VERSION ""

NS_ :

BS_:

BU_: Inverter ACAN Dashboard ECU
VAL_TABLE_ Discharge 1 "Discharge Enabled" 0 "Discharge Disabled" ;
VAL_TABLE_ Enabled 1 "Enabled" 0 "Disabled" ;
VAL_TABLE_ Direction 1 "Forward" 0 "Reverse" ;
VAL_TABLE_ Fault_POST 1073741824 "Brake Shorted" 536870912 "Reserved" 268435456 "Reserved" 134217728 "Reserved" 67108864 "EEPROM Update Required" 33554432 "EEPROM Data Out of Range" 16777216 "EEPROM Checksum Invalid" 8388608 "Pre-Charge Voltage Failure" 4194304 "Pre-Charge Timeout" 2097152 "DC Bus Voltage Low" 1048576 "DC Bus Voltage High" 524288 "1.5V Sense Voltage High" 262144 "1.5V Sense Voltage Low" 131072 "2.5V Sense Voltage High" 65536 "2.5V Sense Voltage Low" 32768 "12V Sense Voltage High" 16384 "12V Sense Voltage Low" 8192 "5V Sense Voltage High" 4096 "5V Sense Voltage Low" 2048 "Gate Drive PCB Temperature High" 1024 "Gate Drive PCB Temperature Low" 512 "Control PCB Temperature High" 256 "Control PCB Temperature Low" 128 "Module Temperature High" 64 "Module Temperature Low" 32 "Current Sensor High" 16 "Current Sensor Low" 8 "Accelerator Open" 4 "Accelerator Shorted" 2 "HW Over-current Fault" 1 "Hardware Gate/Desaturation Fault" 0 "No Faults" -2147483648 "Brake Open" ;
VAL_TABLE_ Button 1 "High" 0 "Low" ;

BO_ 3221225472 VECTOR__INDEPENDENT_SIG_MSG: 0 Vector__XXX
 SG_ Error_POST_Fault : 0|32@1+ (1,0) [0|4294967295] "Enumerable" Vector__XXX
 SG_ APPS_2_Scaled : 0|16@1+ (1,0) [0|65535] "ADC" Vector__XXX

BO_ 1797 TMP__ECU_Message_Status: 2 Vector__XXX
 SG_ TMP_message_received : 0|1@1+ (1,0) [0|1] "Bool" Vector__XXX
 SG_ TMP_message_not_received_count : 8|8@1+ (1,0) [0|1] "Count" Vector__XXX

BO_ 1795 TMP_SEND_REQUEST: 4 Vector__XXX
 SG_ TMP_Torque : 16|16@1+ (0.1,0) [0|65535] "Nm" Vector__XXX
 SG_ TMP_APPS_1 : 0|16@1+ (1,0) [0|65535] "ADC" Vector__XXX

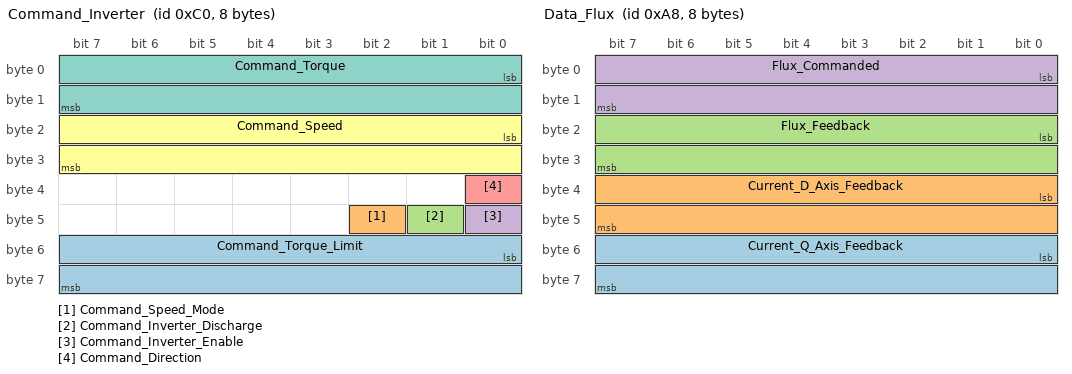
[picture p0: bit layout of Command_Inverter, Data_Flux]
BO_ 192 Command_Inverter: 8 ECU
 SG_ Command_Torque_Limit : 48|16@1- (0.1,0) [-3276.8|3276.7] "Newton Meters"  Inverter
 SG_ Command_Speed_Mode : 42|1@1+ (1,0) [0|1] "Boolean"  Inverter
 SG_ Command_Inverter_Discharge : 41|1@1+ (1,0) [0|1] "Boolean"  Inverter
 SG_ Command_Inverter_Enable : 40|1@1+ (1,0) [0|1] "Boolean"  Inverter
 SG_ Command_Direction : 32|1@1+ (1,0) [0|1] "Boolean"  Inverter
 SG_ Command_Speed : 16|16@1- (1,0) [-32768|32767] "RPM"  Inverter
 SG_ Command_Torque : 0|16@1- (0.1,0) [-3276.8|3276.7] "Newton Meters"  Inverter

BO_ 168 Data_Flux: 8 Inverter
 SG_ Current_Q_Axis_Feedback : 48|16@1- (0.1,0) [-3276.8|3276.7] "Amps" Vector__XXX
 SG_ Current_D_Axis_Feedback : 32|16@1- (0.1,0) [-3276.8|3276.7] "Amps" Vector__XXX
 SG_ Flux_Feedback : 16|16@1- (0.001,0) [-32.768|32.767] "Webers" Vector__XXX
 SG_ Flux_Commanded : 0|16@1- (0.001,0) [-32.768|32.767] "Webers" Vector__XXX

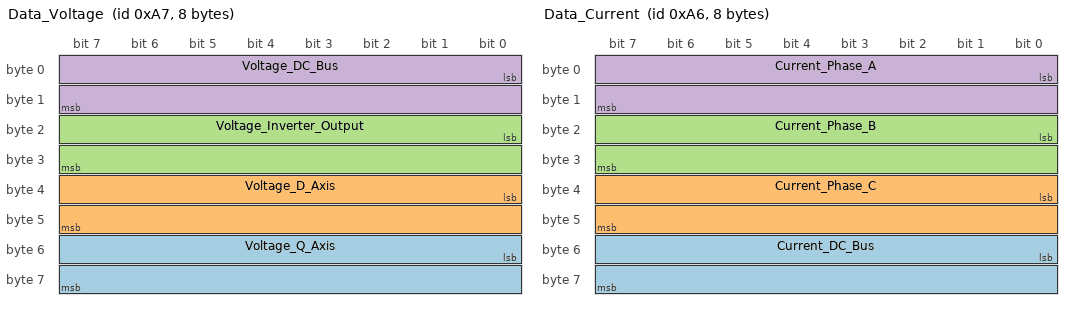
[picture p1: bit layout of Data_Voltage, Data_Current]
BO_ 167 Data_Voltage: 8 Inverter
 SG_ Voltage_Q_Axis : 48|16@1- (0.1,0) [-3276.8|3276.7] "Volts" Vector__XXX
 SG_ Voltage_D_Axis : 32|16@1- (0.1,0) [-3276.8|3276.7] "Volts" Vector__XXX
 SG_ Voltage_Inverter_Output : 16|16@1- (0.1,0) [-3276.8|3276.7] "Volts" Vector__XXX
 SG_ Voltage_DC_Bus : 0|16@1- (0.1,0) [-3276.8|3276.7] "Volts" Vector__XXX

BO_ 166 Data_Current: 8 Inverter
 SG_ Current_DC_Bus : 48|16@1- (0.1,0) [-3276.8|3276.7] "Amps" Vector__XXX
 SG_ Current_Phase_C : 32|16@1- (0.1,0) [-3276.8|3276.7] "Amps" Vector__XXX
 SG_ Current_Phase_B : 16|16@1- (0.1,0) [-3276.8|3276.7] "Amps" Vector__XXX
 SG_ Current_Phase_A : 0|16@1- (0.1,0) [-3276.8|3276.7] "Amps" Vector__XXX

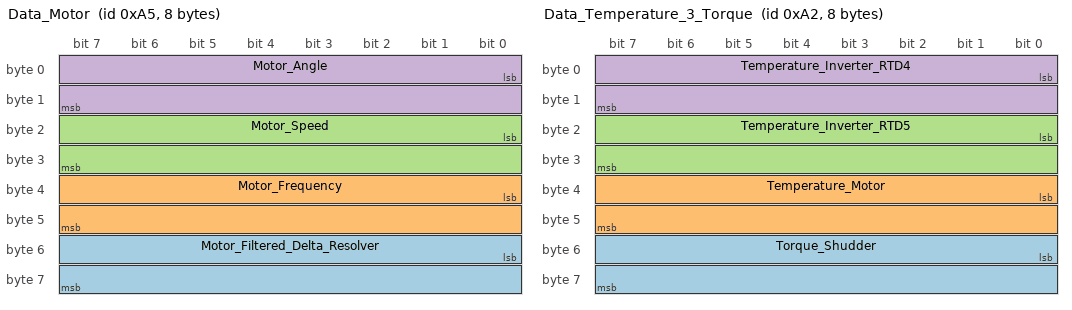
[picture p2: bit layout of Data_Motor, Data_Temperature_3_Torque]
BO_ 165 Data_Motor: 8 Inverter
 SG_ Motor_Filtered_Delta_Resolver : 48|16@1- (0.1,0) [-359.9|359.9] "Degrees" Vector__XXX
 SG_ Motor_Frequency : 32|16@1- (0.1,0) [-3276.8|3276.7] "Hz" Vector__XXX
 SG_ Motor_Speed : 16|16@1- (1,0) [-32768|32767] "RPM" Vector__XXX
 SG_ Motor_Angle : 0|16@1- (0.1,0) [-359.9|359.9] "Degrees" Vector__XXX

BO_ 162 Data_Temperature_3_Torque: 8 Inverter
 SG_ Torque_Shudder : 48|16@1- (0.1,0) [-3276.8|3276.7] "Newton Meters" Vector__XXX
 SG_ Temperature_Motor : 32|16@1- (0.1,0) [-3276.8|3276.7] "Celcius" Vector__XXX
 SG_ Temperature_Inverter_RTD5 : 16|16@1- (0.1,0) [-3276.8|3276.7] "Celcius" Vector__XXX
 SG_ Temperature_Inverter_RTD4 : 0|16@1- (0.1,0) [-3276.8|3276.7] "Celcius" Vector__XXX

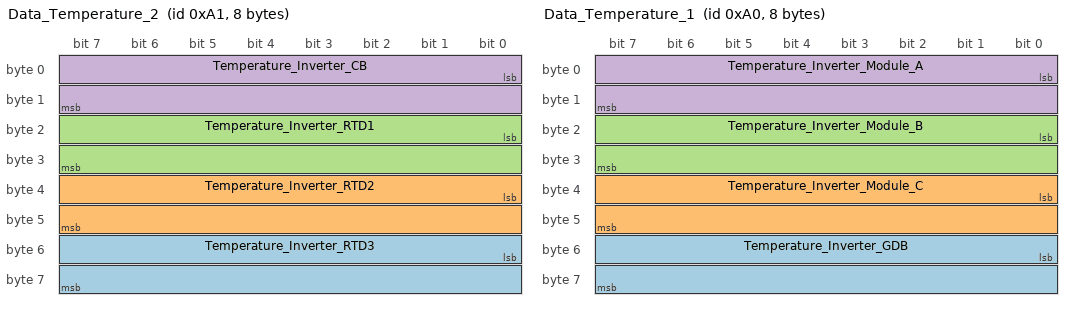
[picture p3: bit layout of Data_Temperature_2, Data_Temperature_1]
BO_ 161 Data_Temperature_2: 8 Inverter
 SG_ Temperature_Inverter_RTD3 : 48|16@1- (0.1,0) [-3276.8|3276.7] "Celcius" Vector__XXX
 SG_ Temperature_Inverter_RTD2 : 32|16@1- (0.1,0) [-3276.8|3276.7] "Celcius" Vector__XXX
 SG_ Temperature_Inverter_RTD1 : 16|16@1- (0.1,0) [-3276.8|3276.7] "Celcius" Vector__XXX
 SG_ Temperature_Inverter_CB : 0|16@1- (0.1,0) [-3276.8|3276.7] "Celcius" Vector__XXX

BO_ 160 Data_Temperature_1: 8 Inverter
 SG_ Temperature_Inverter_GDB : 48|16@1- (0.1,0) [-3276.8|3276.7] "Celcius" Vector__XXX
 SG_ Temperature_Inverter_Module_C : 32|16@1- (0.1,0) [-3276.8|3276.7] "Celcius" Vector__XXX
 SG_ Temperature_Inverter_Module_B : 16|16@1- (0.1,0) [-3276.8|3276.7] "Celcius" Vector__XXX
 SG_ Temperature_Inverter_Module_A : 0|16@1- (0.1,0) [-3276.8|3276.7] "Celcius" Vector__XXX

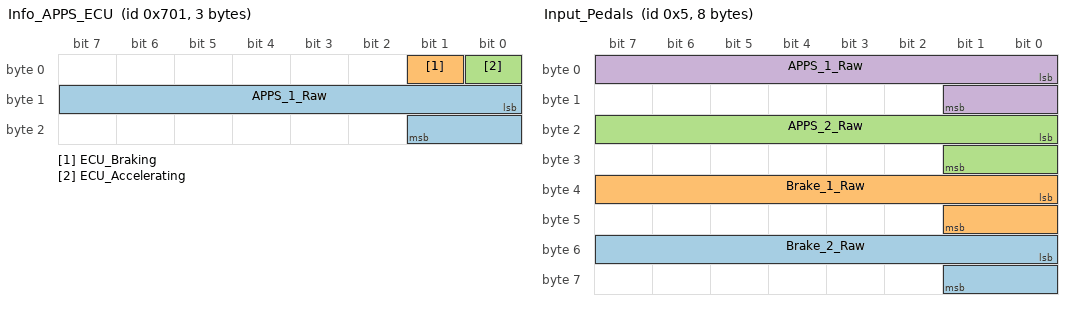
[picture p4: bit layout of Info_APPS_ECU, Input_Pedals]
BO_ 1793 Info_APPS_ECU: 3 ECU
 SG_ APPS_1_Raw : 8|10@1+ (1,0) [0|1023] "ADC" Vector__XXX
 SG_ ECU_Braking : 1|1@1+ (1,0) [0|255] "Boolean" Vector__XXX
 SG_ ECU_Accelerating : 0|1@1+ (1,0) [0|1] "Boolean" Vector__XXX

BO_ 5 Input_Pedals: 8 ACAN
 SG_ Brake_2_Raw : 48|10@1+ (1,0) [0|1023] "ADC"  ECU
 SG_ Brake_1_Raw : 32|10@1+ (1,0) [0|1023] "ADC"  ECU
 SG_ APPS_2_Raw : 16|10@1+ (1,0) [0|1023] "ADC"  ECU
 SG_ APPS_1_Raw : 0|10@1+ (1,0) [0|1023] "ADC"  ECU

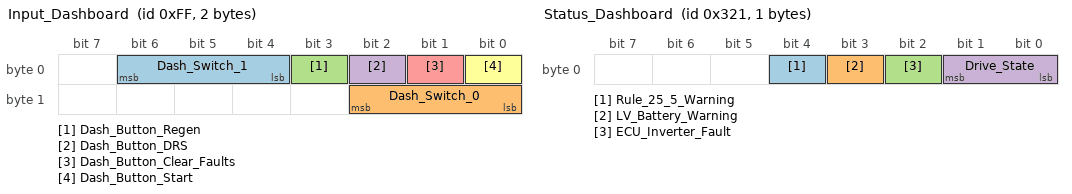
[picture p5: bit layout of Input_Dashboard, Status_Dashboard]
BO_ 255 Input_Dashboard: 2 Dashboard
 SG_ Dash_Switch_1 : 4|3@1+ (1,0) [0|7] "Enumerable"  ECU
 SG_ Dash_Switch_0 : 8|3@1+ (1,0) [0|7] "Enumerable"  ECU
 SG_ Dash_Button_Regen : 3|1@1+ (1,0) [0|1] "Boolean"  ECU
 SG_ Dash_Button_DRS : 2|1@1+ (1,0) [0|1] "Boolean"  ECU
 SG_ Dash_Button_Clear_Faults : 1|1@1+ (1,0) [0|1] "Boolean"  ECU
 SG_ Dash_Button_Start : 0|1@1+ (1,0) [0|1] "Boolean"  ECU

BO_ 144 Input_Steering_Angle: 2 Dashboard
 SG_ Steering_Angle : 0|16@1- (0.01,0) [-32768|32767] "Degrees" Vector__XXX

BO_ 250 Data_Torque: 2 ECU
 SG_ Torque_Percentage_Regen : 8|8@1+ (1,0) [0|255] "Percent" Vector__XXX
 SG_ Torque_Percentage_Max : 0|8@1+ (1,0) [0|255] "Percent" Vector__XXX

BO_ 291 Command_DRS_Status: 1 ECU
 SG_ DRS_Enabled : 0|1@1+ (1,0) [0|1] "Boolean" Vector__XXX

BO_ 1345 Status_ECU_2: 4 ECU
 SG_ Resistance_IMD : 16|16@1+ (1,0) [0|65535] "ADC" Vector__XXX
 SG_ LV_Battery_Charge : 0|16@1+ (0.0196888,0) [0|1290.305508] "Volts" Vector__XXX

BO_ 801 Status_Dashboard: 1 ECU
 SG_ Rule_25_5_Warning : 4|1@1+ (1,0) [0|1] "Boolean"  Dashboard
 SG_ LV_Battery_Warning : 3|1@1+ (1,0) [0|1] "Boolean"  Dashboard
 SG_ ECU_Inverter_Fault : 2|1@1+ (1,0) [0|1] "Boolean"  Dashboard
 SG_ Drive_State : 0|2@1+ (1,0) [0|3] "Enumerable"  Dashboard

CM_ BU_ Inverter "RMS PM100 DX Inverter";
CM_ BU_ ACAN "Pedal Input";
CM_ BU_ Dashboard "Dashboard";
CM_ BU_ ECU "Vehicle ECU";
CM_ BO_ 3221225472 "This is a message for not used signals, created by Vector CANdb++ DBC OLE DB Provider.";
CM_ SG_ 3221225472 Error_POST_Fault "Inverter POST Fault Code";
CM_ SG_ 3221225472 APPS_2_Scaled "Scaled APPS 2";
CM_ BO_ 1797 "Temporary debug message";
CM_ SG_ 1797 TMP_message_received "ECU bool APPS message received";
CM_ SG_ 1797 TMP_message_not_received_count "ECU count of messages not received from APPS";
CM_ BO_ 1795 "Temporary debug message";
CM_ BO_ 192 "ECU Inverter Command";
CM_ SG_ 192 Command_Torque_Limit "ECU Torque Limit Command";
CM_ SG_ 192 Command_Speed_Mode "ECU Inverter Speed Mode Command";
CM_ SG_ 192 Command_Inverter_Discharge "ECU Inverter Discharge Enable Command";
CM_ SG_ 192 Command_Inverter_Enable "ECU Inverter Enable Command";
CM_ SG_ 192 Command_Direction "ECU Direction Command";
CM_ SG_ 192 Command_Speed "ECU Speed Command";
CM_ SG_ 192 Command_Torque "ECU Torque Command";
CM_ BO_ 168 "Inverter Flux Information";
CM_ SG_ 168 Current_Q_Axis_Feedback "Inverter Q-Axis Current Feedback";
CM_ SG_ 168 Current_D_Axis_Feedback "Inverter D-Axis Current Feedback";
CM_ SG_ 168 Flux_Feedback "Inverter Feedback Flux";
CM_ SG_ 168 Flux_Commanded "Inverter Commanded Flux";
CM_ BO_ 167 "Inverter Voltage Information";
CM_ SG_ 167 Voltage_Q_Axis "Inverter Q-Axis Voltage. Refers to Phase B-C when disabled";
CM_ SG_ 167 Voltage_D_Axis "Inverter D-Axis Voltage. Refers to Phase A-B Voltage when disabled";
CM_ SG_ 167 Voltage_Inverter_Output "Voltage of the Inverters Output";
CM_ SG_ 167 Voltage_DC_Bus "Voltage of the Inverter DC Bus";
CM_ BO_ 166 "Current information from the Inverter";
CM_ SG_ 166 Current_DC_Bus "Current of the Inverter DC Bus";
CM_ SG_ 166 Current_Phase_C "Current of Inverter Phase C";
CM_ SG_ 166 Current_Phase_B "Current of Inverter Phase B";
CM_ SG_ 166 Current_Phase_A "Current of Inverter Phase A";
CM_ BO_ 165 "Inverter Data about the Motor";
CM_ SG_ 165 Motor_Speed "The Angluar Velocity of the Motor";
CM_ SG_ 165 Motor_Angle "Current Angle of the Motor";
CM_ BO_ 162 "Inverter Temperature Message 3 & Torque Shudder";
CM_ SG_ 162 Temperature_Inverter_RTD5 "Temperature of RTD #5";
CM_ SG_ 162 Temperature_Inverter_RTD4 "Temperature of RTD #4";
CM_ BO_ 161 "Inverter Temperature Message 2";
CM_ SG_ 161 Temperature_Inverter_RTD3 "Temperature of RTD #3";
CM_ SG_ 161 Temperature_Inverter_RTD2 "Temperature of RTD #2";
CM_ SG_ 161 Temperature_Inverter_RTD1 "Temperature of RTD #1";
CM_ SG_ 161 Temperature_Inverter_CB "Temperature of the Control Board";
CM_ BO_ 160 "Inverter Temperature Message #1";
CM_ SG_ 160 Temperature_Inverter_GDB "Temperature of the Gate Driver Board";
CM_ SG_ 160 Temperature_Inverter_Module_C "Temperature of IGBT Module, Phase C";
CM_ SG_ 160 Temperature_Inverter_Module_B "Temperature of IGBT Module, Phase B";
CM_ SG_ 160 Temperature_Inverter_Module_A "Temperature of IGBT Module, Phase A";
CM_ BO_ 1793 "ECU Interpretted ACAN information";
CM_ SG_ 1793 APPS_1_Raw "APPS Value 0";
CM_ SG_ 1793 ECU_Braking "Brake Pressed";
CM_ SG_ 1793 ECU_Accelerating "Accelerator Pressed";
CM_ BO_ 5 "Pedal Input";
CM_ SG_ 5 Brake_2_Raw "Brake Value 1";
CM_ SG_ 5 Brake_1_Raw "Brake Value 0";
CM_ SG_ 5 APPS_2_Raw "APPS Value 1";
CM_ SG_ 5 APPS_1_Raw "APPS Value 0";
CM_ BO_ 255 "Dashboard Input";
CM_ SG_ 255 Dash_Switch_1 "Switch for Driving Mode";
CM_ SG_ 255 Dash_Switch_0 "Dashboard Switch 0";
CM_ SG_ 255 Dash_Button_Regen "Regen Button";
CM_ SG_ 255 Dash_Button_DRS "DRS Button";
CM_ SG_ 255 Dash_Button_Clear_Faults "Clear Inverter Faults Button";
CM_ SG_ 255 Dash_Button_Start "Start Button";
CM_ BO_ 144 "Steering Angle";
CM_ SG_ 144 Steering_Angle "Steering Angle";
CM_ BO_ 250 "Torque Percentage";
CM_ SG_ 250 Torque_Percentage_Regen "Regen Percentage";
CM_ SG_ 250 Torque_Percentage_Max "Maximum Torque Percentage";
CM_ BO_ 291 "Command to enable/disable DRS";
CM_ SG_ 291 DRS_Enabled "DRS Status";
CM_ BO_ 1345 "Miscellaneous Vehicle Statuses";
CM_ SG_ 1345 Resistance_IMD "IMD Resistance";
CM_ SG_ 1345 LV_Battery_Charge "LV Battery Charge";
CM_ BO_ 801 "Drive state and general errors for dashboard";
CM_ SG_ 801 Rule_25_5_Warning "25/5 Plausibility";
CM_ SG_ 801 LV_Battery_Warning "LV Battery Low Charge Warning";
CM_ SG_ 801 ECU_Inverter_Fault "Inverter Status";
CM_ SG_ 801 Drive_State "Vehicle Status";
BA_DEF_  "BusType" STRING ;
BA_DEF_DEF_  "BusType" "CAN";
VAL_ 3221225472 Error_POST_Fault 1073741824 "Brake Shorted" 536870912 "Reserved" 268435456 "Reserved" 134217728 "Reserved" 67108864 "EEPROM Update Required" 33554432 "EEPROM Data Out of Range" 16777216 "EEPROM Checksum Invalid" 8388608 "Pre-Charge Voltage Failure" 4194304 "Pre-Charge Timeout" 2097152 "DC Bus Voltage Low" 1048576 "DC Bus Voltage High" 524288 "1.5V Sense Voltage High" 262144 "1.5V Sense Voltage Low" 131072 "2.5V Sense Voltage High" 65536 "2.5V Sense Voltage Low" 32768 "12V Sense Voltage High" 16384 "12V Sense Voltage Low" 8192 "5V Sense Voltage High" 4096 "5V Sense Voltage Low" 2048 "Gate Drive PCB Temperature High" 1024 "Gate Drive PCB Temperature Low" 512 "Control PCB Temperature High" 256 "Control PCB Temperature Low" 128 "Module Temperature High" 64 "Module Temperature Low" 32 "Current Sensor High" 16 "Current Sensor Low" 8 "Accelerator Open" 4 "Accelerator Shorted" 2 "HW Over-current Fault" 1 "Hardware Gate/Desaturation Fault" 0 "No Faults" -2147483648 "Brake Open" ;
VAL_ 192 Command_Inverter_Discharge 1 "Discharge Enabled" 0 "Discharge Disabled" ;
VAL_ 192 Command_Inverter_Enable 1 "Enabled" 0 "Disabled" ;
VAL_ 192 Command_Direction 1 "Forward" 0 "Reverse" ;
VAL_ 1793 ECU_Accelerating 1 "Pressed" 0 "Not Pressed" ;
VAL_ 255 Dash_Switch_1 7 "Null" 6 "Beans" 5 "Accel" 4 "Autocross" 3 "Endurance" 2 "Skidpad" 1 "Dan" 0 "Debug" ;
VAL_ 255 Dash_Switch_0 7 "Position 7" 6 "Position 6" 5 "Position 5" 4 "Position 4" 3 "Position 3" 2 "Position 2" 1 "Position 1" 0 "Position 0" ;
VAL_ 255 Dash_Button_Regen 1 "High" 0 "Low" ;
VAL_ 255 Dash_Button_DRS 1 "High" 0 "Low" ;
VAL_ 255 Dash_Button_Clear_Faults 1 "High" 0 "Low" ;
VAL_ 255 Dash_Button_Start 1 "High" 0 "Low" ;
VAL_ 291 DRS_Enabled 1 "Enabled" 0 "Disabled" ;
VAL_ 801 Rule_25_5_Warning 1 "25/5 Implausible" 0 "25/5 Plausible" ;
VAL_ 801 LV_Battery_Warning 1 "Battery Charge Low" 0 "Battery Charged" ;
VAL_ 801 ECU_Inverter_Fault 1 "Fault Detected" 0 "No Faults" ;
VAL_ 801 Drive_State 3 "High Voltage, Drive Enabled" 2 "High Voltage, Drive Disabled" 1 "Low Voltage, Drive Disabled" 0 "Initialization" ;
